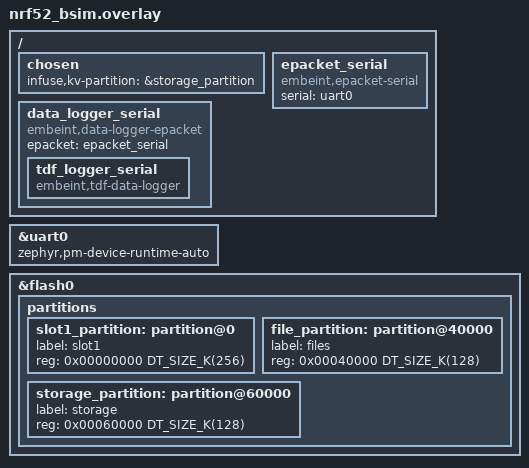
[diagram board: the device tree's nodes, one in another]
/*
 * Copyright (c) 2025 Embeint Holdings Pty Ltd
 * SPDX-License-Identifier: FSL-1.1-ALv2
 */

#include <common/infuse_bluetooth.dtsi>

/ {
	chosen {
		infuse,kv-partition = &storage_partition;
	};

	epacket_serial: epacket_serial {
		compatible = "embeint,epacket-serial";
		serial = <&uart0>;
	};

	data_logger_serial: data_logger_serial {
		compatible = "embeint,data-logger-epacket", "embeint,data-logger";
		epacket = <&epacket_serial>;

		tdf_logger_serial: tdf_logger_serial {
			compatible = "embeint,tdf-data-logger";
		};
	};
};

&uart0 {
	zephyr,pm-device-runtime-auto;
};

/* Allocate other useful testing Infuse-IoT partitions */
/delete-node/ &storage_partition;

&flash0 {
	partitions {
		slot1_partition: partition@0 {
			label = "slot1";
			reg = <0x00000000 DT_SIZE_K(256)>;
		};
		file_partition: partition@40000 {
			label = "files";
			reg = <0x00040000 DT_SIZE_K(128)>;
		};
		storage_partition: partition@60000 {
			label = "storage";
			reg = <0x00060000 DT_SIZE_K(128)>;
		};
	};
};
